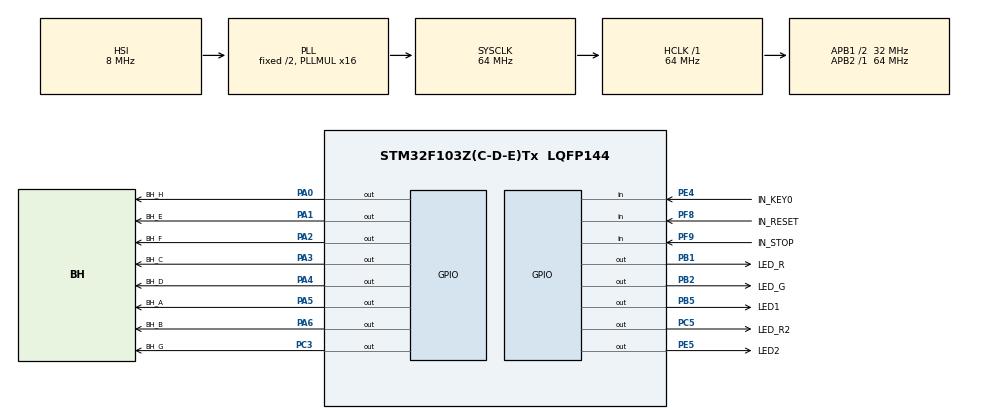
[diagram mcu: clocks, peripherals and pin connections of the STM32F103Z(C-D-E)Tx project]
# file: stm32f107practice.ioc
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Mcu.Family=STM32F1
Mcu.Name=STM32F103Z(C-D-E)Tx
Mcu.Package=LQFP144
NVIC.PriorityGroup=NVIC_PRIORITYGROUP_4
PA0-WKUP.GPIO_Label=BH_H
PA0-WKUP.Signal=GPIO_Output
PA1.GPIO_Label=BH_E
PA1.Signal=GPIO_Output
PA13.Mode=Serial_Wire
PA13.Signal=SYS_JTMS-SWDIO
PA14.Mode=Serial_Wire
PA14.Signal=SYS_JTCK-SWCLK
PA2.GPIO_Label=BH_F
PA2.Signal=GPIO_Output
PA3.GPIO_Label=BH_C
PA3.Signal=GPIO_Output
PA4.GPIO_Label=BH_D
PA4.Signal=GPIO_Output
PA5.GPIO_Label=BH_A
PA5.Signal=GPIO_Output
PA6.GPIO_Label=BH_B
PA6.Signal=GPIO_Output
PB1.GPIO_Label=LED_R
PB1.PinState=GPIO_PIN_RESET
PB1.Signal=GPIO_Output
PB2.GPIO_Label=LED_G
PB2.Signal=GPIO_Output
PB5.GPIO_Label=LED1
PB5.GPIO_Speed=GPIO_SPEED_FREQ_LOW
PB5.PinState=GPIO_PIN_RESET
PB5.Signal=GPIO_Output
PC3.GPIO_Label=BH_G
PC3.Signal=GPIO_Output
PC5.GPIO_Label=LED_R2
PC5.Signal=GPIO_Output
PE4.GPIO_Label=IN_KEY0
PE4.GPIO_PuPd=GPIO_PULLUP
PE4.Signal=GPIO_Input
PE5.GPIO_Label=LED2
PE5.GPIO_Speed=GPIO_SPEED_FREQ_LOW
PE5.PinState=GPIO_PIN_RESET
PE5.Signal=GPIO_Output
PF8.GPIO_Label=IN_RESET
PF8.GPIO_PuPd=GPIO_PULLDOWN
PF8.Signal=GPIO_Input
PF9.GPIO_Label=IN_STOP
PF9.GPIO_PuPd=GPIO_PULLDOWN
PF9.Signal=GPIO_Input
ProjectManager.HeapSize=0x200
ProjectManager.StackSize=0x400
ProjectManager.TargetToolchain=STM32CubeIDE
RCC.AHBFreq_Value=64000000
RCC.APB1CLKDivider=RCC_HCLK_DIV2
RCC.APB1Freq_Value=32000000
RCC.APB1TimFreq_Value=64000000
RCC.APB2Freq_Value=64000000
RCC.APB2TimFreq_Value=64000000
RCC.HCLKFreq_Value=64000000
RCC.PLLMUL=RCC_PLL_MUL16
RCC.SYSCLKFreq_VALUE=64000000
RCC.SYSCLKSource=RCC_SYSCLKSOURCE_PLLCLK
RCC.USBFreq_Value=64000000
board=custom

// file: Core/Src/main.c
/* USER CODE BEGIN Header */
/**
  ******************************************************************************
  * @file           : main.c
  * @brief          : Main program body
  ******************************************************************************
  * @attention
  *
  * <h2><center>&copy; Copyright (c) 2021 STMicroelectronics.
  * All rights reserved.</center></h2>
  *
  * This software component is licensed by ST under BSD 3-Clause license,
  * the "License"; You may not use this file except in compliance with the
  * License. You may obtain a copy of the License at:
  *                        opensource.org/licenses/BSD-3-Clause
  *
  ******************************************************************************
  */
/* USER CODE END Header */
#include "main.h"

/* USER CODE BEGIN Includes */

#include "lib/led1.h"
#include "lib/5611bh.h"

/* USER CODE END Includes */

void SystemClock_Config(void);
static void MX_GPIO_Init(void);

int main(void)
{

  /* MCU Configuration--------------------------------------------------------*/

  /* Reset of all peripherals, Initializes the Flash interface and the Systick. */
  HAL_Init();

  /* Configure the system clock */
  SystemClock_Config();

  /* Initialize all configured peripherals */
  MX_GPIO_Init();

  /* Infinite loop */
  /* USER CODE BEGIN WHILE */
  SHOW_LED();
//  BH_init();
//  int inputStop;
//  int inputReset;
//  GPIO_SetBits(0);
  while (1)
  {
	  SCAN_Keys();
//	  inputStop = HAL_GPIO_ReadPin(IN_STOP_GPIO_Port, IN_STOP_Pin);
//	  inputReset = HAL_GPIO_ReadPin(IN_RESET_GPIO_Port, IN_RESET_Pin);
//	  SET_top(inputStop);
////	  SET_reset(inputReset);
//	  if (inputStop == 0) {
//		  HIND_LED();
//	  } else {
//		  SHOW_LED();
//	  }
//	  HAL_Delay(100);
//	  if (inputStop ==1) {
//	  		ADD_number(2);
//	  	} else {
//	  		ADD_number(0);
//	  	}
//	  ADD_number(inputStop);
//	  _stop_flag = inputStop;
//	  GPIO_SetBits(inputStop);
//	  LED_Init();
    /* USER CODE END WHILE */

  }
}

void SystemClock_Config(void)
{
  RCC_OscInitTypeDef RCC_OscInitStruct = {0};
  RCC_ClkInitTypeDef RCC_ClkInitStruct = {0};

  /** Initializes the RCC Oscillators according to the specified parameters
  * in the RCC_OscInitTypeDef structure.
  */
  RCC_OscInitStruct.OscillatorType = RCC_OSCILLATORTYPE_HSI;
  RCC_OscInitStruct.HSIState = RCC_HSI_ON;
  RCC_OscInitStruct.HSICalibrationValue = RCC_HSICALIBRATION_DEFAULT;
  RCC_OscInitStruct.PLL.PLLState = RCC_PLL_ON;
  RCC_OscInitStruct.PLL.PLLSource = RCC_PLLSOURCE_HSI_DIV2;
  RCC_OscInitStruct.PLL.PLLMUL = RCC_PLL_MUL16;
  if (HAL_RCC_OscConfig(&RCC_OscInitStruct) != HAL_OK)
  {
    Error_Handler();
  }
  /** Initializes the CPU, AHB and APB buses clocks
  */
  RCC_ClkInitStruct.ClockType = RCC_CLOCKTYPE_HCLK|RCC_CLOCKTYPE_SYSCLK
                              |RCC_CLOCKTYPE_PCLK1|RCC_CLOCKTYPE_PCLK2;
  RCC_ClkInitStruct.SYSCLKSource = RCC_SYSCLKSOURCE_PLLCLK;
  RCC_ClkInitStruct.AHBCLKDivider = RCC_SYSCLK_DIV1;
  RCC_ClkInitStruct.APB1CLKDivider = RCC_HCLK_DIV2;
  RCC_ClkInitStruct.APB2CLKDivider = RCC_HCLK_DIV1;

  if (HAL_RCC_ClockConfig(&RCC_ClkInitStruct, FLASH_LATENCY_2) != HAL_OK)
  {
    Error_Handler();
  }
}

static void MX_GPIO_Init(void)
{
  GPIO_InitTypeDef GPIO_InitStruct = {0};

  /* GPIO Ports Clock Enable */
  __HAL_RCC_GPIOE_CLK_ENABLE();
  __HAL_RCC_GPIOF_CLK_ENABLE();
  __HAL_RCC_GPIOC_CLK_ENABLE();
  __HAL_RCC_GPIOA_CLK_ENABLE();
  __HAL_RCC_GPIOB_CLK_ENABLE();

  /*Configure GPIO pin Output Level */
  HAL_GPIO_WritePin(LED2_GPIO_Port, LED2_Pin, GPIO_PIN_RESET);

  /*Configure GPIO pin Output Level */
  HAL_GPIO_WritePin(GPIOC, BH_G_Pin|LED_R2_Pin, GPIO_PIN_RESET);

  /*Configure GPIO pin Output Level */
  HAL_GPIO_WritePin(GPIOA, BH_H_Pin|BH_E_Pin|BH_F_Pin|BH_C_Pin
                          |BH_D_Pin|BH_A_Pin|BH_B_Pin, GPIO_PIN_RESET);

  /*Configure GPIO pin Output Level */
  HAL_GPIO_WritePin(GPIOB, LED_R_Pin|LED_G_Pin|LED1_Pin, GPIO_PIN_RESET);

  /*Configure GPIO pin : IN_KEY0_Pin */
  GPIO_InitStruct.Pin = IN_KEY0_Pin;
  GPIO_InitStruct.Mode = GPIO_MODE_INPUT;
  GPIO_InitStruct.Pull = GPIO_PULLUP;
  HAL_GPIO_Init(IN_KEY0_GPIO_Port, &GPIO_InitStruct);

  /*Configure GPIO pin : LED2_Pin */
  GPIO_InitStruct.Pin = LED2_Pin;
  GPIO_InitStruct.Mode = GPIO_MODE_OUTPUT_PP;
  GPIO_InitStruct.Pull = GPIO_NOPULL;
  GPIO_InitStruct.Speed = GPIO_SPEED_FREQ_LOW;
  HAL_GPIO_Init(LED2_GPIO_Port, &GPIO_InitStruct);

  /*Configure GPIO pins : IN_RESET_Pin IN_STOP_Pin */
  GPIO_InitStruct.Pin = IN_RESET_Pin|IN_STOP_Pin;
  GPIO_InitStruct.Mode = GPIO_MODE_INPUT;
  GPIO_InitStruct.Pull = GPIO_PULLDOWN;
  HAL_GPIO_Init(GPIOF, &GPIO_InitStruct);

  /*Configure GPIO pins : BH_G_Pin LED_R2_Pin */
  GPIO_InitStruct.Pin = BH_G_Pin|LED_R2_Pin;
  GPIO_InitStruct.Mode = GPIO_MODE_OUTPUT_PP;
  GPIO_InitStruct.Pull = GPIO_NOPULL;
  GPIO_InitStruct.Speed = GPIO_SPEED_FREQ_LOW;
  HAL_GPIO_Init(GPIOC, &GPIO_InitStruct);

  /*Configure GPIO pins : BH_H_Pin BH_E_Pin BH_F_Pin BH_C_Pin
                           BH_D_Pin BH_A_Pin BH_B_Pin */
  GPIO_InitStruct.Pin = BH_H_Pin|BH_E_Pin|BH_F_Pin|BH_C_Pin
                          |BH_D_Pin|BH_A_Pin|BH_B_Pin;
  GPIO_InitStruct.Mode = GPIO_MODE_OUTPUT_PP;
  GPIO_InitStruct.Pull = GPIO_NOPULL;
  GPIO_InitStruct.Speed = GPIO_SPEED_FREQ_LOW;
  HAL_GPIO_Init(GPIOA, &GPIO_InitStruct);

  /*Configure GPIO pins : LED_R_Pin LED_G_Pin LED1_Pin */
  GPIO_InitStruct.Pin = LED_R_Pin|LED_G_Pin|LED1_Pin;
  GPIO_InitStruct.Mode = GPIO_MODE_OUTPUT_PP;
  GPIO_InitStruct.Pull = GPIO_NOPULL;
  GPIO_InitStruct.Speed = GPIO_SPEED_FREQ_LOW;
  HAL_GPIO_Init(GPIOB, &GPIO_InitStruct);

}

void Error_Handler(void)
{
  __disable_irq();
  while (1)
  {
  }
}

/************************ (C) COPYRIGHT STMicroelectronics *****END OF FILE****/
